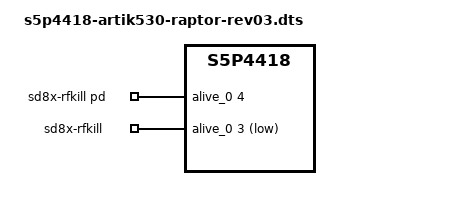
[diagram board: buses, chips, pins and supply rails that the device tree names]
/*
 * Copyright (C) 2016  Nexell Co., Ltd.
 * Author: Youngbok, Park <ybpark@nexell.co.kr>
 *
 * This program is free software; you can redistribute it and/or
 * modify it under the terms of the GNU General Public License
 * as published by the Free Software Foundation; either version 2
 * of the License, or (at your option) any later version.
 *
 * This program is distributed in the hope that it will be useful,
 * but WITHOUT ANY WARRANTY; without even the implied warranty of
 * MERCHANTABILITY or FITNESS FOR A PARTICULAR PURPOSE.  See the
 * GNU General Public License for more details.
 *
 * You should have received a copy of the GNU General Public License
 * along with this program.  If not, see <http://www.gnu.org/licenses/>.
 */

/dts-v1/;
#include "s5p4418-artik530-raptor-common.dtsi"
/ {
	sd8x-rfkill {
		compatible = "mrvl,sd8x-rfkill";
		sd-host = <&dw_mmc_1>;
		pd-gpio = <&alive_0 4 0>; /* AliveGPIO4=WLAN_BT_PDN output*/
		gpios = <&alive_0 3 1>; /* AliveGPIO3=WLAN_HOST_WAKE, input */
		status = "okay";
	};
};
